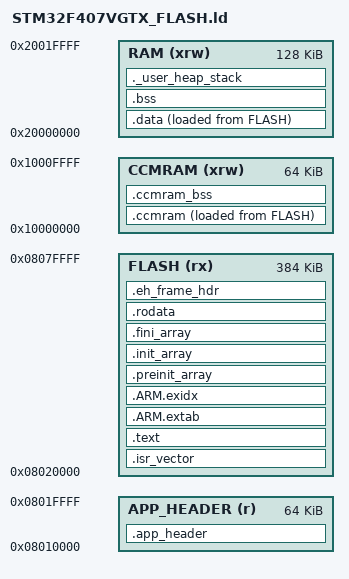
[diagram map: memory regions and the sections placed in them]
/*
******************************************************************************
**
** @file        : STM32F407VGTX_FLASH.ld
**
** @author      : Auto-generated by STM32CubeIDE, customized for bootloader app
**
** @brief       : Linker script for STM32F407VGTx
**                Application Header: 0x08010000, 64 KB
**                Application Code:   0x08020000, 384 KB
**                CCMRAM:             64 KB
**                RAM:                128 KB
**
******************************************************************************
*/

/* Entry Point */
ENTRY(Reset_Handler)

/* Minimum heap and stack sizes */
_Min_Heap_Size  = 0x200;
_Min_Stack_Size = 0x400;

/* Memories definition */
MEMORY
{
  CCMRAM     (xrw) : ORIGIN = 0x10000000, LENGTH = 64K
  RAM        (xrw) : ORIGIN = 0x20000000, LENGTH = 128K
  APP_HEADER (r)   : ORIGIN = 0x08010000, LENGTH = 64K
  FLASH      (rx)  : ORIGIN = 0x08020000, LENGTH = 384K
}

/* Highest address of the user mode stack */
_estack = ORIGIN(RAM) + LENGTH(RAM);

/* Sections */
SECTIONS
{
  /* Application vector table at 0x08020000 */
  .isr_vector :
  {
    . = ALIGN(4);
    __app_vector_table_start__ = .;

    KEEP(*(.isr_vector))

    . = ALIGN(4);
    __app_vector_table_end__ = .;
  } > FLASH

  /* Application code and read-only data */
  .text :
  {
    . = ALIGN(4);

    *(.text)
    *(.text*)
    *(.glue_7)
    *(.glue_7t)
    *(.eh_frame)

    KEEP(*(.init))
    KEEP(*(.fini))

    . = ALIGN(4);
    _etext = .;
  } > FLASH

  /* ARM exception-unwind tables */
  .ARM.extab :
  {
    . = ALIGN(4);
    *(.ARM.extab* .gnu.linkonce.armextab.*)
    . = ALIGN(4);
  } > FLASH

  .ARM.exidx :
  {
    . = ALIGN(4);
    __exidx_start = .;
    *(.ARM.exidx*)
    __exidx_end = .;
    . = ALIGN(4);
  } > FLASH

  /* C/C++ initialization arrays */
  .preinit_array :
  {
    . = ALIGN(4);
    PROVIDE_HIDDEN(__preinit_array_start = .);
    KEEP(*(.preinit_array*))
    PROVIDE_HIDDEN(__preinit_array_end = .);
    . = ALIGN(4);
  } > FLASH

  .init_array :
  {
    . = ALIGN(4);
    PROVIDE_HIDDEN(__init_array_start = .);
    KEEP(*(SORT(.init_array.*)))
    KEEP(*(.init_array*))
    PROVIDE_HIDDEN(__init_array_end = .);
    . = ALIGN(4);
  } > FLASH

  .fini_array :
  {
    . = ALIGN(4);
    PROVIDE_HIDDEN(__fini_array_start = .);
    KEEP(*(SORT(.fini_array.*)))
    KEEP(*(.fini_array*))
    PROVIDE_HIDDEN(__fini_array_end = .);
    . = ALIGN(4);
  } > FLASH

  /* Constant data */
  .rodata :
  {
    . = ALIGN(4);
    *(.rodata)
    *(.rodata*)
    . = ALIGN(4);
  } > FLASH

  /* Exception frame header if generated */
  .eh_frame_hdr :
  {
    *(.eh_frame_hdr)
  } > FLASH

  /* Flash load address of initialized RAM data */
  _sidata = LOADADDR(.data);

  /* Initialized variables copied from FLASH to RAM */
  .data :
  {
    . = ALIGN(4);
    _sdata = .;
    __data_start__ = .;

    *(.data)
    *(.data*)

    . = ALIGN(4);
    _edata = .;
    __data_end__ = .;
  } > RAM AT > FLASH

  /* Initialized variables copied from FLASH to CCMRAM */
  _siccmram = LOADADDR(.ccmram);

  .ccmram :
  {
    . = ALIGN(4);
    _sccmram = .;
    __ccmram_start__ = .;

    *(.ccmram)
    *(.ccmram*)

    . = ALIGN(4);
    _eccmram = .;
    __ccmram_end__ = .;
  } > CCMRAM AT > FLASH

  /* Uninitialized variables in RAM */
  .bss (NOLOAD) :
  {
    . = ALIGN(4);
    _sbss = .;
    __bss_start__ = .;

    *(.bss)
    *(.bss*)
    *(COMMON)

    . = ALIGN(4);
    _ebss = .;
    __bss_end__ = .;
  } > RAM

  /* Uninitialized variables explicitly placed in CCMRAM */
  .ccmram_bss (NOLOAD) :
  {
    . = ALIGN(4);
    __ccmram_bss_start__ = .;

    *(.ccmram_bss)
    *(.ccmram_bss*)

    . = ALIGN(4);
    __ccmram_bss_end__ = .;
  } > CCMRAM

  /* Heap and stack reservation */
  ._user_heap_stack (NOLOAD) :
  {
    . = ALIGN(8);
    PROVIDE(end = .);
    PROVIDE(_end = .);

    . = . + _Min_Heap_Size;
    . = . + _Min_Stack_Size;

    . = ALIGN(8);
  } > RAM

  /* Remove unused standard-library metadata sections */
  /DISCARD/ :
  {
    libc.a   (*)
    libm.a   (*)
    libgcc.a (*)
  }

  /* ARM build attributes */
  .ARM.attributes 0 :
  {
    *(.ARM.attributes)
  }
  
  .app_header :
  {
    KEEP(*(.app_header))
  } > APP_HEADER
}


